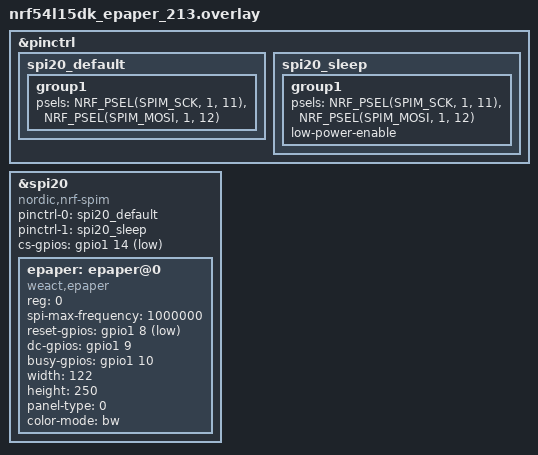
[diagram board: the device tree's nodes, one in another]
/*
 * Copyright (c) 2025 WeAct Studio
 * SPDX-License-Identifier: Apache-2.0
 *
 * Device tree overlay for nRF54L15-DK with WeAct 2.13" E-Paper Display
 *
 * Pin connections:
 * - P1.08 -> RES (Reset)
 * - P1.09 -> DC (Data/Command)
 * - P1.10 -> BUSY
 * - P1.14 -> CS (SPI)
 * - P1.11 -> SCK (SPI)
 * - P1.12 -> MOSI (SPI)
 */

&pinctrl {
	spi20_default: spi20_default {
		group1 {
			psels = <NRF_PSEL(SPIM_SCK, 1, 11)>,
				<NRF_PSEL(SPIM_MOSI, 1, 12)>;
		};
	};

	spi20_sleep: spi20_sleep {
		group1 {
			psels = <NRF_PSEL(SPIM_SCK, 1, 11)>,
				<NRF_PSEL(SPIM_MOSI, 1, 12)>;
			low-power-enable;
		};
	};
};

&spi20 {
	compatible = "nordic,nrf-spim";
	status = "okay";
	pinctrl-0 = <&spi20_default>;
	pinctrl-1 = <&spi20_sleep>;
	pinctrl-names = "default", "sleep";
	cs-gpios = <&gpio1 14 GPIO_ACTIVE_LOW>;

	epaper: epaper@0 {
		compatible = "weact,epaper";
		reg = <0>;
		spi-max-frequency = <1000000>;
		reset-gpios = <&gpio1 8 GPIO_ACTIVE_LOW>;
		dc-gpios = <&gpio1 9 GPIO_ACTIVE_HIGH>;
		busy-gpios = <&gpio1 10 GPIO_ACTIVE_HIGH>;
		width = <122>;
		height = <250>;
		panel-type = <0>; /* EPD213_219 */
		color-mode = "bw";
	};
};
